# STM8AL31E88 register map
Vendor: STMicroelectronics; Series: STM8L/STM8AL, high/medium+ density; File version: 1.0
CPU: other r1p0, big endian, no MPU, no FPU, 4 interrupt priority bits
Registers are 8-bit, read-write, reset 0x0 unless marked. A register's access mark holds for its fields unless they carry their own. Offsets are from the block's base; [hi:lo] are bit positions; {n}, {i} and the like mark numbered series; 'fields as' and 'values as' point back to an identical list.

## AES
Base 0x000053D0
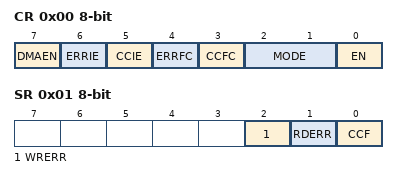
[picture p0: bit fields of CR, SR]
0x00 CR — AES control register
  [7] DMAEN, [6] ERRIE, [5] CCIE, [4] ERRFC, [3] CCFC, [2:1] MODE, [0] EN
0x01 SR — AES status register
  [2] WRERR, [1] RDERR, [0] CCF
0x02 DINR — AES data input register
0x03 DOUTR — AES data output register

## BEEP
Base 0x000050F0
0x00 CSR1 — BEEP control/status register 1
  [0] MSR
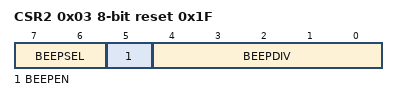
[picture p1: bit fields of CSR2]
0x03 CSR2 reset 0x1F — BEEP control/status register 2
  [7:6] BEEPSEL, [5] BEEPEN, [4:0] BEEPDIV

## CLK
Base 0x000050C0
0x00 CKDIVR reset 0x3 — Clock master divider register
  [2:0] CKM
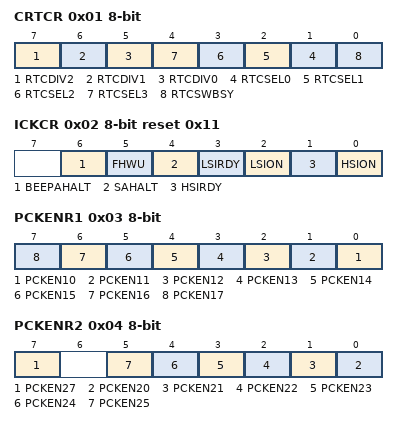
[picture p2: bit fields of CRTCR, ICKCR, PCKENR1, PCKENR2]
0x01 CRTCR — Clock RTC register
  [7] RTCDIV2, [6] RTCDIV1, [5] RTCDIV0, [n+1] RTCSEL{n} (n=0..3), [0] RTCSWBSY
0x02 ICKCR reset 0x11 — Internal clock control register
  [6] BEEPAHALT, [5] FHWU, [4] SAHALT, [3] LSIRDY, [2] LSION, [1] HSIRDY, [0] HSION
0x03 PCKENR1 — Peripheral clock gating register 1
  [n-10] PCKEN{n} (n=10..17)
0x04 PCKENR2 — Peripheral clock gating register 2
  [7] PCKEN27, [n-20] PCKEN{n} (n=20..25)
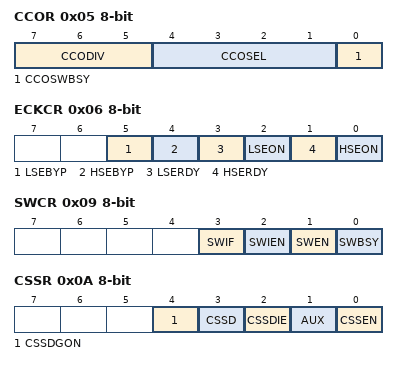
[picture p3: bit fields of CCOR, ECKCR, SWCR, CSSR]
0x05 CCOR — Configurable clock control register
  [7:5] CCODIV, [4:1] CCOSEL, [0] CCOSWBSY
0x06 ECKCR — External clock control register
  [5] LSEBYP, [4] HSEBYP, [3] LSERDY, [2] LSEON, [1] HSERDY, [0] HSEON
0x07 SCSR reset 0x1 — System clock status register
  [7:0] CKM
0x08 SWR reset 0x1 — System clock switch register
  [7:0] SWI
0x09 SWCR — Clock switch control register
  [3] SWIF, [2] SWIEN, [1] SWEN, [0] SWBSY
0x0A CSSR — Clock security system register
  [4] CSSDGON, [3] CSSD, [2] CSSDIE, [1] AUX, [0] CSSEN
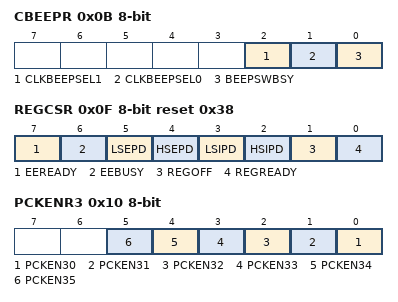
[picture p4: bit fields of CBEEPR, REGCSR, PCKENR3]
0x0B CBEEPR — Clock BEEP register
  [2] CLKBEEPSEL1, [1] CLKBEEPSEL0, [0] BEEPSWBSY
0x0C HSICALR — HSI calibration register
  [7:0] HSICAL
0x0D HSITRIMR — HSI clock calibration trimming register
  [7:0] HSITRIM
0x0E HSIUNLCKR — HSI unlock register
  [7:0] HSIUNLCK
0x0F REGCSR reset 0x38 — Main regulator control status register
  [7] EEREADY, [6] EEBUSY, [5] LSEPD, [4] HSEPD, [3] LSIPD, [2] HSIPD, [1] REGOFF, [0] REGREADY
0x10 PCKENR3 — Peripheral clock gating register 3
  [n-30] PCKEN{n} (n=30..35)

## COMP1_2
Base 0x00005440
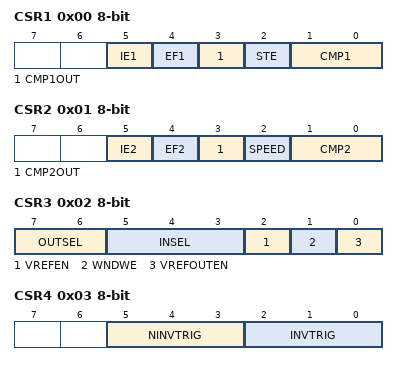
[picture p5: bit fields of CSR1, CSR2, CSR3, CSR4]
0x00 CSR1 — Comparator control and status register 1
  [5] IE1, [4] EF1, [3] CMP1OUT, [2] STE, [1:0] CMP1
0x01 CSR2 — Comparator control and status register 2
  [5] IE2, [4] EF2, [3] CMP2OUT, [2] SPEED, [1:0] CMP2
0x02 CSR3 — Comparator control and status register 3
  [7:6] OUTSEL, [5:3] INSEL, [2] VREFEN, [1] WNDWE, [0] VREFOUTEN
0x03 CSR4 — Comparator control and status register 4
  [5:3] NINVTRIG, [2:0] INVTRIG
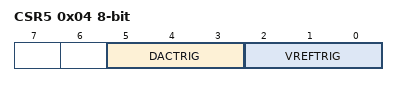
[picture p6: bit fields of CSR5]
0x04 CSR5 — Comparator control and status register 5
  [5:3] DACTRIG, [2:0] VREFTRIG

## CPU
Base 0x00007F00
0x00 A — Accumulator
0x01 PCE — Program counter extended
0x02 PCH — Program counter high
0x03 PCL — Program counter low
0x04 XH — X index register high
0x05 XL — X index register low
0x06 YH — Y index register high
0x07 YL — Y index register low
0x08 SPH reset 0x3 — Stack pointer high
0x09 SPL reset 0xFF — Stack pointer low
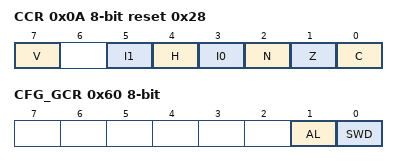
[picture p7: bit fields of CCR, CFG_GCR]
0x0A CCR reset 0x28 — Condition code register
  [7] V, [5] I1, [4] H, [3] I0, [2] N, [1] Z, [0] C
0x60 CFG_GCR — Global configuration register
  [1] AL, [0] SWD

## DAC
Base 0x00005380
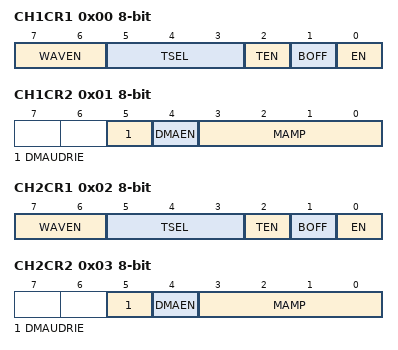
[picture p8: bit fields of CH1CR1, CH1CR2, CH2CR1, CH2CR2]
0x00 CH1CR1 — DAC channel 1 control register 1
  [7:6] WAVEN, [5:3] TSEL, [2] TEN, [1] BOFF, [0] EN
0x01 CH1CR2 — DAC channel 1 control register 2
  [5] DMAUDRIE, [4] DMAEN, [3:0] MAMP
0x02 CH2CR1 — DAC channel 2 control register 1
  [7:6] WAVEN, [5:3] TSEL, [2] TEN, [1] BOFF, [0] EN
0x03 CH2CR2 — DAC channel 2 control register 2
  [5] DMAUDRIE, [4] DMAEN, [3:0] MAMP
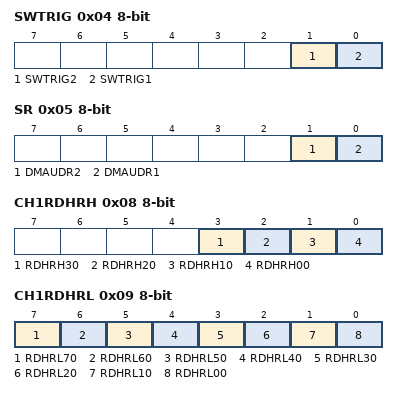
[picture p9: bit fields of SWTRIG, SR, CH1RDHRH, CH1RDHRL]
0x04 SWTRIG — DAC software trigger register
  [1] SWTRIG2, [0] SWTRIG1
0x05 SR — DAC status register
  [1] DMAUDR2, [0] DMAUDR1
0x08 CH1RDHRH — DAC channel 1 right aligned data holding register high
  [3] RDHRH30, [2] RDHRH20, [1] RDHRH10, [0] RDHRH00
0x09 CH1RDHRL — DAC channel 1 right aligned data holding register low
  [7] RDHRL70, [6] RDHRL60, [5] RDHRL50, [4] RDHRL40, [3] RDHRL30, [2] RDHRL20, [1] RDHRL10, [0] RDHRL00
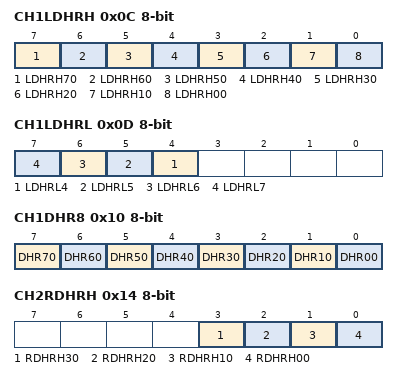
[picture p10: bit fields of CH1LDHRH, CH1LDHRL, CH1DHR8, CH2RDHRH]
0x0C CH1LDHRH — DAC channel 1 left aligned data holding register high
  [7] LDHRH70, [6] LDHRH60, [5] LDHRH50, [4] LDHRH40, [3] LDHRH30, [2] LDHRH20, [1] LDHRH10, [0] LDHRH00
0x0D CH1LDHRL — DAC channel 1 left aligned data holding register low
  [n] LDHRL{n} (n=4..7)
0x10 CH1DHR8 — DAC channel 1 8-bit data holding register
  [7] DHR70, [6] DHR60, [5] DHR50, [4] DHR40, [3] DHR30, [2] DHR20, [1] DHR10, [0] DHR00
0x14 CH2RDHRH — DAC channel 2 right aligned data holding register high
  [3] RDHRH30, [2] RDHRH20, [1] RDHRH10, [0] RDHRH00
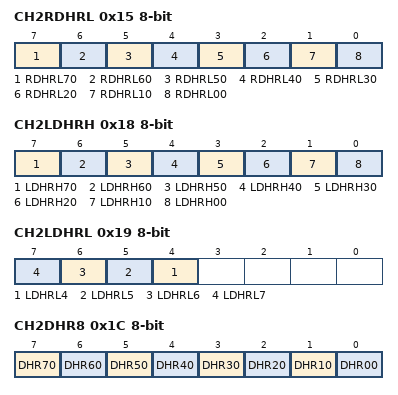
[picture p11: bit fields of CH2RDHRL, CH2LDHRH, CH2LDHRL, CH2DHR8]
0x15 CH2RDHRL — DAC channel 2 right aligned data holding register low
  fields as CH1RDHRL
0x18 CH2LDHRH — DAC channel 2 left aligned data holding register high
  fields as CH1LDHRH
0x19 CH2LDHRL — DAC channel 2 left aligned data holding register low
  [n] LDHRL{n} (n=4..7)
0x1C CH2DHR8 — DAC channel 2 8-bit data holding register
  fields as CH1DHR8
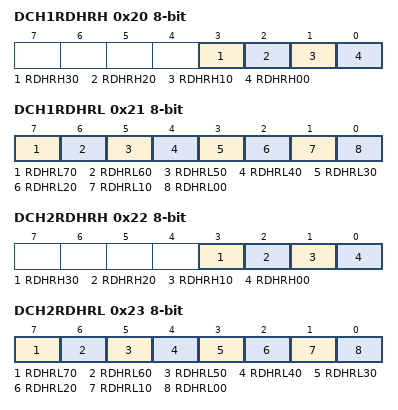
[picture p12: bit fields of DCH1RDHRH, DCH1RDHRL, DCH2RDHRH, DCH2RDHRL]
0x20 DCH1RDHRH — DAC channel 1 right aligned data holding register high
  [3] RDHRH30, [2] RDHRH20, [1] RDHRH10, [0] RDHRH00
0x21 DCH1RDHRL — DAC channel 1 right aligned data holding register low
  fields as CH1RDHRL
0x22 DCH2RDHRH — DAC channel 2 right aligned data holding register high
  [3] RDHRH30, [2] RDHRH20, [1] RDHRH10, [0] RDHRH00
0x23 DCH2RDHRL — DAC channel 2 right aligned data holding register low
  fields as CH1RDHRL
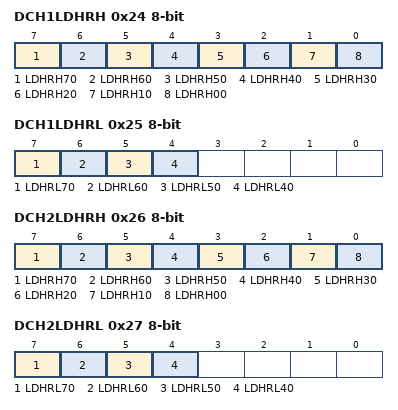
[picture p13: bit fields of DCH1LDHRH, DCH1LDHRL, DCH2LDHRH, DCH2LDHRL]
0x24 DCH1LDHRH — DAC channel 1left aligned data holding register high
  fields as CH1LDHRH
0x25 DCH1LDHRL — DAC channel 1left aligned data holding register low
  [7] LDHRL70, [6] LDHRL60, [5] LDHRL50, [4] LDHRL40
0x26 DCH2LDHRH — DAC channel 2 left aligned data holding register high
  fields as CH1LDHRH
0x27 DCH2LDHRL — DAC channel 2 left aligned data holding register low
  [7] LDHRL70, [6] LDHRL60, [5] LDHRL50, [4] LDHRL40
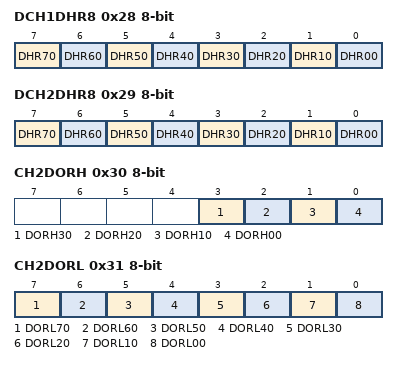
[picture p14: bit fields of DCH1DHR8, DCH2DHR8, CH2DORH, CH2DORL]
0x28 DCH1DHR8 — DAC channel 1 8-bit mode data holding register
  fields as CH1DHR8
0x29 DCH2DHR8 — DAC channel 2 8-bit mode data holding register
  fields as CH1DHR8
0x2C DORH — DAC data output register high
  [3:0] DORH
0x2D DORL — DAC data output register low
0x30 CH2DORH — DAC channel 2 data output register high
  [3] DORH30, [2] DORH20, [1] DORH10, [0] DORH00
0x31 CH2DORL — DAC channel 2 data output register low
  [7] DORL70, [6] DORL60, [5] DORL50, [4] DORL40, [3] DORL30, [2] DORL20, [1] DORL10, [0] DORL00
